# RZT2L register map
Vendor: Renesas Electronics Corporation; Series: RZT; File version: 1.20.00
CPU: other r0p0, little endian, MPU, no FPU, VTOR, 4 interrupt priority bits, 624 interrupts
Registers are 32-bit, read-write, reset 0x0 unless marked. A register's access mark holds for its fields unless they carry their own. Offsets are from the block's base; [hi:lo] are bit positions; {n}, {i} and the like mark numbered series; 'fields as' and 'values as' point back to an identical list.

## MBXSEM — Mailbox and Semaphore
Base 0x80240000
{0x0+4i} SEM{i} (i=0..7) — Semaphore Register {i}
  [0] SEM — Semaphore bit
    0=Resource being used; 1=Resource not being used
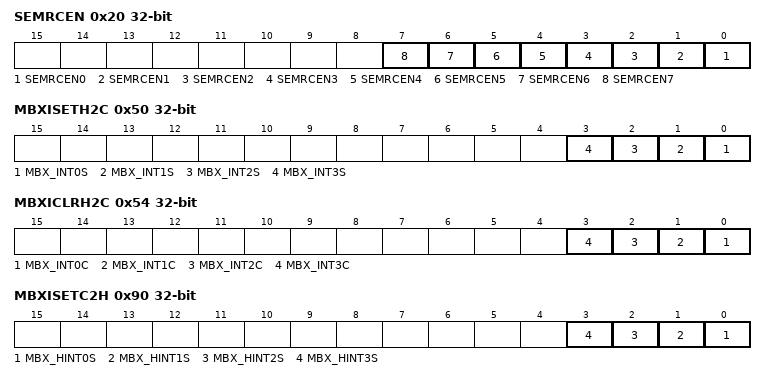
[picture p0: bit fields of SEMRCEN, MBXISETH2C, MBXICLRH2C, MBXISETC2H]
0x20 SEMRCEN — Semaphore Read Clear Enable Register
  [all] fields
    0=Disables read clear function; 1=Enables read clear function
  [n] SEMRCEN{n} (n=0..7)
{0x40+4i} MBXH2C{i} (i=0..3) ro — Host to CR52 Mailbox Register {i}
  [31:0] MBX
0x50 MBXISETH2C ro — Host to CR52 Mailbox Interrupt Set Register
  [n] MBX_INT{n}S (n=0..3) — Generates or indicates MBX_INT{n} interrupt of mailbox from external host CPU to internal Cortex-R52.
0x54 MBXICLRH2C — Host to CR52 Mailbox Interrupt Clear Register
  [n] MBX_INT{n}C (n=0..3) — Clears or indicates MBX_INT{n} interrupt of mailbox from external host CPU to internal Cortex-R52.
{0x80+4i} MBXC2H{i} (i=0..3) — CR52 to Host Mailbox Register {i}
  [31:0] MBX
0x90 MBXISETC2H — CR52 to Host Mailbox Interrupt Set Register
  [n] MBX_HINT{n}S (n=0..3) — Generates or indicates MBX_HINT{n} interrupt of mailbox from internal Cortex-R52 to external host CPU.
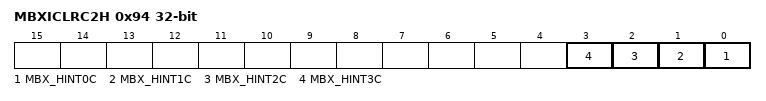
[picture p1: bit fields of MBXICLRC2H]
0x94 MBXICLRC2H ro — CR52 to Host Mailbox Interrupt Clear Register
  [n] MBX_HINT{n}C (n=0..3) — Clears or indicates MBX_HINT{n} interrupt of mailbox from internal Cortex-R52 to external host CPU.

## ELO — Evnet Link Option Setting
Base 0x80281200
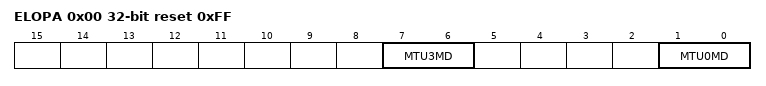
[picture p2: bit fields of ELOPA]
0x00 ELOPA reset 0xFF — Event Link Option Setting Register A
  [7:6] MTU3MD — MTU3 Operation Select
    0=Counting is started; 1=Counting is restarted; 2=Input capture (The MTU3.TCNT value is captured into MTU3.TGRA.); 3=Event is disabled
  [1:0] MTU0MD — MTU0 Operation Select
    0=Counting is started; 1=Counting is restarted; 2=Input capture (The MTU0.TCNT value is captured into MTU0.TGRA.); 3=Event is disabled
0x04 ELOPB reset 0xFF — Event Link Option Setting Register B
  [1:0] MTU4MD — MTU4 Operation Select
    0=Counting is started; 1=Counting is restarted; 2=Input capture (The MTU4.TCNT value is captured into MTU4.TGRA.); 3=Event is disabled

## RWP_NS — Register Write Protection for Non-safety Area
Base 0x80281A10
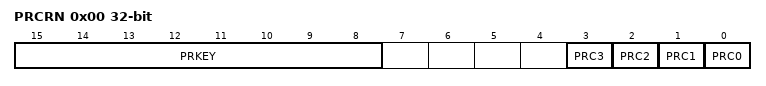
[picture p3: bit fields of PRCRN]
0x00 PRCRN — Non_Safety Area Protect Register
  [15:8] PRKEY wo — PRC Key Code
  [n] PRC{n} (n=0..3) — Protect {n}
    0=Write disabled; 1=Write enabled

## OTP — One-Time Programmable Memory
Base 0x81028000
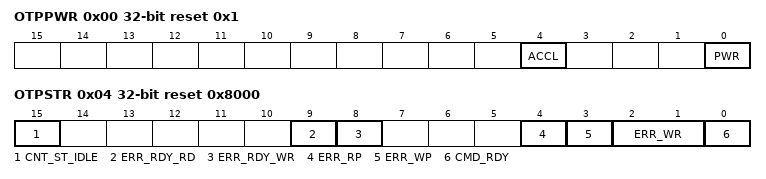
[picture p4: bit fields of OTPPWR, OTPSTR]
0x00 OTPPWR reset 0x1 — OTP Power Control Register
  [4] ACCL — Selects OTP access I/F
    0=Not selected; 1=Selected
  [0] PWR — OTP power on/off setting
    0=Power off; 1=Power on
0x04 OTPSTR reset 0x8000 — OTP Access Status Register
  [15] CNT_ST_IDLE ro — Indicates status of OTP controller
    0=Busy; 1=Idle
  [9] ERR_RDY_RD — OTP read command ready error
  [8] ERR_RDY_WR — OTP write command ready error
  [4] ERR_RP ro — Read protection error
  [3] ERR_WP ro — Write protection error
  [2:1] ERR_WR ro — OTP write status
    0=PASS; 1=Fail due to overwrites; 2=Fail due to compare mismatch; 3=Fail due to overwrites and compare mismatch
  [0] CMD_RDY ro — Indicates whether OTP controller is ready to receive command or not.
    0=Not ready; 1=Ready
0x08 OTPSTAWR — OTP Write Command Register
  [0] STAWR — OTP write start
0x0C OTPADRWR — OTP Write Address Register
  [8:0] ADRWR — OTP write address
0x10 OTPDATAWR — OTP Write Data Register
  [15:0] DATAWR — OTP write data
0x14 OTPADRRD — OTP Read Address Register
  [8:0] ADRRD — OTP read address
0x18 OTPDATARD ro — OTP Read Data Register
  [15:0] DATARD — OTP read data

## PTADR — Port Address Selection
Base 0x81030C00
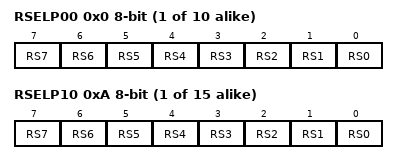
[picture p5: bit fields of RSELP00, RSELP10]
{0x0+i} RSELP0{i} (i=0..9) 8-bit — Port {i} Region Select Register
  [all] fields
    0=Safety region (Address is 0x8103_0xxx); 1=Non safety region (Address is 0x800A_0xxx)
  [n] RS{n} (n=0..7) — Pm_n pin I/O port registers Region Select (n = bit position)
{0x0+i} RSELP{i} (i=10..24) 8-bit — Port {i} Region Select Register
  fields as RSELP00
